# BGM11S12F256GA register map
File version: 4.0.0
CPU: CM4 r0p1, little endian, no MPU, no FPU, 0x3 interrupt priority bits, 0x0 interrupts
Registers are 32-bit, read-write, reset 0x0 unless marked. A register's access mark holds for its fields unless they carry their own. Offsets are from the block's base; [hi:lo] are bit positions; 'fields as' and 'values as' point back to an identical list.

## EMU
Base 0x400E3000
0x00 CTRL — Control Register
  [1] EM2BLOCK — Energy Mode 2 Block
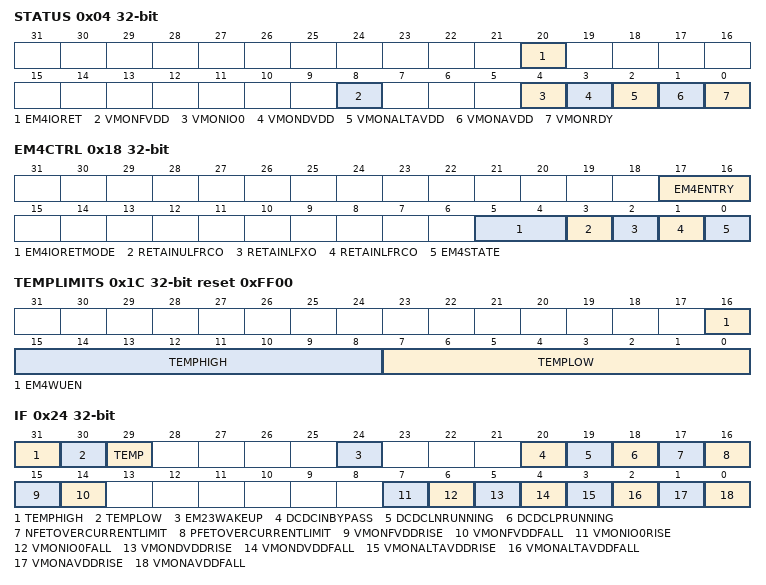
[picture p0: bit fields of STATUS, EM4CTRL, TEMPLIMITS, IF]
0x04 STATUS ro
  [20] EM4IORET — IO Retention Status
  [8] VMONFVDD — VMON VDDFLASH Channel
  [4] VMONIO0 — VMON IOVDD0 Channel
  [3] VMONDVDD — VMON DVDD Channel
  [2] VMONALTAVDD — Alternate VMON AVDD Channel
  [1] VMONAVDD — VMON AVDD Channel
  [0] VMONRDY — VMON Ready
0x08 LOCK — Configuration Lock Register
  [15:0] LOCKKEY — Configuration Lock Key
    0=UNLOCKED; 1=LOCKED
0x0C RAM0CTRL — Memory Control Register
  [3:0] RAMPOWERDOWN — RAM0 Blockset Power-down
    0=NONE (None of the RAM blocks powered down); 8=BLK4 (Power down RAM blocks 4 and above); 12=BLK3TO4 (Power down RAM blocks 3 and above); 14=BLK2TO4 (Power down RAM blocks 2 and above); 15=BLK1TO4 (Power down RAM blocks 1 and above)
0x10 CMD wo — Command Register
  [0] EM4UNLATCH
0x18 EM4CTRL — EM4 Control Register
  [17:16] EM4ENTRY wo — Energy Mode 4 Entry
  [5:4] EM4IORETMODE — EM4 IO Retention Disable
    0=DISABLE (No Retention: Pads enter reset state when entering EM4); 1=EM4EXIT (Retention through EM4: Pads enter reset state when exiting EM4); 2=SWUNLATCH (Retention through EM4 and Wakeup: software writes UNLATCH register to remove retention)
  [3] RETAINULFRCO — ULFRCO Retain During EM4S
  [2] RETAINLFXO — LFXO Retain During EM4
  [1] RETAINLFRCO — LFRCO Retain During EM4
  [0] EM4STATE — Energy Mode 4 State
0x1C TEMPLIMITS reset 0xFF00 — Temperature Limits for Interrupt Generation
  [16] EM4WUEN — Enable EM4 Wakeup Due to Low/high Temperature
  [15:8] TEMPHIGH — Temperature High Limit
  [7:0] TEMPLOW — Temperature Low Limit
0x20 TEMP ro — Value of Last Temperature Measurement
  [7:0] TEMP — Temperature Measurement
0x24 IF ro — Interrupt Flag Register
  [31] TEMPHIGH — Temperature High Limit Reached
  [30] TEMPLOW — Temperature Low Limit Reached
  [29] TEMP — New Temperature Measurement Valid
  [24] EM23WAKEUP — Wakeup IRQ From EM2 and EM3
  [20] DCDCINBYPASS — DCDC is in Bypass
  [19] DCDCLNRUNNING — LN Mode is Running
  [18] DCDCLPRUNNING — LP Mode is Running
  [17] NFETOVERCURRENTLIMIT — NFET Current Limit Hit
  [16] PFETOVERCURRENTLIMIT — PFET Current Limit Hit
  [15] VMONFVDDRISE — VMON VDDFLASH Channel Rise
  [14] VMONFVDDFALL — VMON VDDFLASH Channel Fall
  [7] VMONIO0RISE — VMON IOVDD0 Channel Rise
  [6] VMONIO0FALL — VMON IOVDD0 Channel Fall
  [5] VMONDVDDRISE — VMON DVDD Channel Rise
  [4] VMONDVDDFALL — VMON DVDD Channel Fall
  [3] VMONALTAVDDRISE — Alternate VMON AVDD Channel Rise
  [2] VMONALTAVDDFALL — Alternate VMON AVDD Channel Fall
  [1] VMONAVDDRISE — VMON AVDD Channel Rise
  [0] VMONAVDDFALL — VMON AVDD Channel Fall
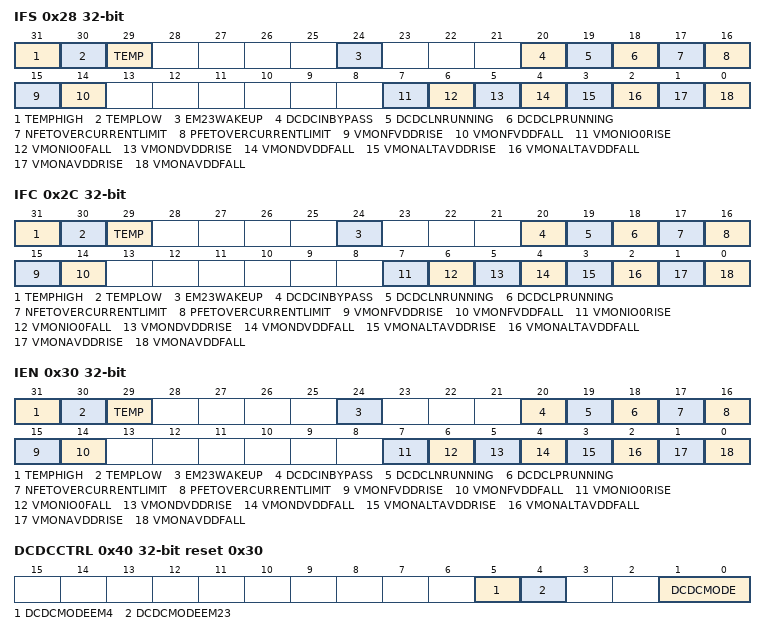
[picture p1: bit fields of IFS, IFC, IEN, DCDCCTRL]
0x28 IFS wo — Interrupt Flag Set Register
  [31] TEMPHIGH — Set TEMPHIGH Interrupt Flag
  [30] TEMPLOW — Set TEMPLOW Interrupt Flag
  [29] TEMP — Set TEMP Interrupt Flag
  [24] EM23WAKEUP — Set EM23WAKEUP Interrupt Flag
  [20] DCDCINBYPASS — Set DCDCINBYPASS Interrupt Flag
  [19] DCDCLNRUNNING — Set DCDCLNRUNNING Interrupt Flag
  [18] DCDCLPRUNNING — Set DCDCLPRUNNING Interrupt Flag
  [17] NFETOVERCURRENTLIMIT — Set NFETOVERCURRENTLIMIT Interrupt Flag
  [16] PFETOVERCURRENTLIMIT — Set PFETOVERCURRENTLIMIT Interrupt Flag
  [15] VMONFVDDRISE — Set VMONFVDDRISE Interrupt Flag
  [14] VMONFVDDFALL — Set VMONFVDDFALL Interrupt Flag
  [7] VMONIO0RISE — Set VMONIO0RISE Interrupt Flag
  [6] VMONIO0FALL — Set VMONIO0FALL Interrupt Flag
  [5] VMONDVDDRISE — Set VMONDVDDRISE Interrupt Flag
  [4] VMONDVDDFALL — Set VMONDVDDFALL Interrupt Flag
  [3] VMONALTAVDDRISE — Set VMONALTAVDDRISE Interrupt Flag
  [2] VMONALTAVDDFALL — Set VMONALTAVDDFALL Interrupt Flag
  [1] VMONAVDDRISE — Set VMONAVDDRISE Interrupt Flag
  [0] VMONAVDDFALL — Set VMONAVDDFALL Interrupt Flag
0x2C IFC wo — Interrupt Flag Clear Register
  [31] TEMPHIGH — Clear TEMPHIGH Interrupt Flag
  [30] TEMPLOW — Clear TEMPLOW Interrupt Flag
  [29] TEMP — Clear TEMP Interrupt Flag
  [24] EM23WAKEUP — Clear EM23WAKEUP Interrupt Flag
  [20] DCDCINBYPASS — Clear DCDCINBYPASS Interrupt Flag
  [19] DCDCLNRUNNING — Clear DCDCLNRUNNING Interrupt Flag
  [18] DCDCLPRUNNING — Clear DCDCLPRUNNING Interrupt Flag
  [17] NFETOVERCURRENTLIMIT — Clear NFETOVERCURRENTLIMIT Interrupt Flag
  [16] PFETOVERCURRENTLIMIT — Clear PFETOVERCURRENTLIMIT Interrupt Flag
  [15] VMONFVDDRISE — Clear VMONFVDDRISE Interrupt Flag
  [14] VMONFVDDFALL — Clear VMONFVDDFALL Interrupt Flag
  [7] VMONIO0RISE — Clear VMONIO0RISE Interrupt Flag
  [6] VMONIO0FALL — Clear VMONIO0FALL Interrupt Flag
  [5] VMONDVDDRISE — Clear VMONDVDDRISE Interrupt Flag
  [4] VMONDVDDFALL — Clear VMONDVDDFALL Interrupt Flag
  [3] VMONALTAVDDRISE — Clear VMONALTAVDDRISE Interrupt Flag
  [2] VMONALTAVDDFALL — Clear VMONALTAVDDFALL Interrupt Flag
  [1] VMONAVDDRISE — Clear VMONAVDDRISE Interrupt Flag
  [0] VMONAVDDFALL — Clear VMONAVDDFALL Interrupt Flag
0x30 IEN — Interrupt Enable Register
  [31] TEMPHIGH — TEMPHIGH Interrupt Enable
  [30] TEMPLOW — TEMPLOW Interrupt Enable
  [29] TEMP — TEMP Interrupt Enable
  [24] EM23WAKEUP — EM23WAKEUP Interrupt Enable
  [20] DCDCINBYPASS — DCDCINBYPASS Interrupt Enable
  [19] DCDCLNRUNNING — DCDCLNRUNNING Interrupt Enable
  [18] DCDCLPRUNNING — DCDCLPRUNNING Interrupt Enable
  [17] NFETOVERCURRENTLIMIT — NFETOVERCURRENTLIMIT Interrupt Enable
  [16] PFETOVERCURRENTLIMIT — PFETOVERCURRENTLIMIT Interrupt Enable
  [15] VMONFVDDRISE — VMONFVDDRISE Interrupt Enable
  [14] VMONFVDDFALL — VMONFVDDFALL Interrupt Enable
  [7] VMONIO0RISE — VMONIO0RISE Interrupt Enable
  [6] VMONIO0FALL — VMONIO0FALL Interrupt Enable
  [5] VMONDVDDRISE — VMONDVDDRISE Interrupt Enable
  [4] VMONDVDDFALL — VMONDVDDFALL Interrupt Enable
  [3] VMONALTAVDDRISE — VMONALTAVDDRISE Interrupt Enable
  [2] VMONALTAVDDFALL — VMONALTAVDDFALL Interrupt Enable
  [1] VMONAVDDRISE — VMONAVDDRISE Interrupt Enable
  [0] VMONAVDDFALL — VMONAVDDFALL Interrupt Enable
0x34 PWRLOCK — Regulator and Supply Lock Register
  [15:0] LOCKKEY — Regulator and Supply Configuration Lock Key
    0=UNLOCKED; 1=LOCKED
0x38 PWRCFG — Power Configuration Register
  [3:0] PWRCFG — Power Configuration
    0=STARTUP (Power up configuration. Works with any external configuration.); 2=DCDCTODVDD (Configured: DCDC control logic is enabled.)
0x3C PWRCTRL — Power Control Register
  [5] ANASW — Analog Switch Selection
0x40 DCDCCTRL reset 0x30 — DCDC Control
  [5] DCDCMODEEM4 — DCDC Mode EM4H
  [4] DCDCMODEEM23
  [1:0] DCDCMODE — Regulator Mode
    0=BYPASS (DCDC regulator is operating in bypass mode. Prior to configuring DCDCMODE=BYPASS, software must set EMU_DCDCCLIMCTRL.BYPLIMEN=1 to prevent excessive current between VREGVDD and DVDD supplies.); 1=LOWNOISE (DCDC regulator is operating in low noise mode.); 2=LOWPOWER (DCDC regulator is operating in low power mode.); 3=OFF (DCDC regulator is off and the bypass switch is off. Note: DVDD must be supplied externally)
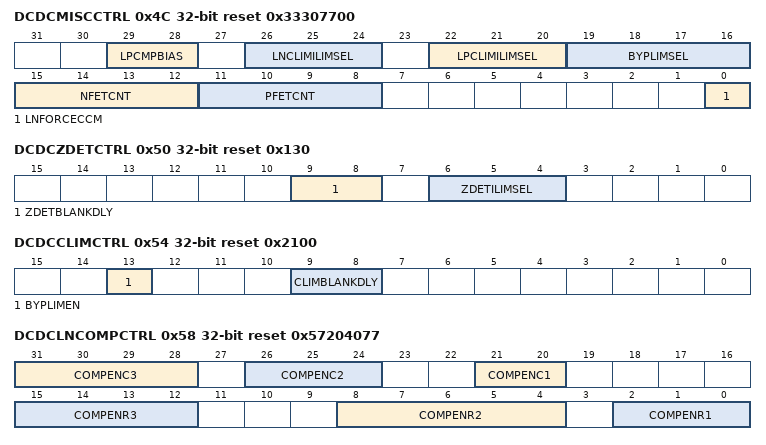
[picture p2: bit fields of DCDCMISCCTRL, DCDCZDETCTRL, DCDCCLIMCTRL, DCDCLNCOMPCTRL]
0x4C DCDCMISCCTRL reset 0x33307700 — DCDC Miscellaneous Control Register
  [29:28] LPCMPBIAS — LP Mode Comparator Bias Selection
    0=BIAS0 (Maximum load current less than 75uA.); 1=BIAS1 (Maximum load current less than 500uA.); 2=BIAS2 (Maximum load current less than 2.5mA.); 3=BIAS3 (Maximum load current less than 10mA.)
  [26:24] LNCLIMILIMSEL — Current Limit Level Selection for Current Limiter in LN Mode
  [22:20] LPCLIMILIMSEL — Current Limit Level Selection for Current Limiter in LP Mode
  [19:16] BYPLIMSEL — Current Limit in Bypass Mode
  [15:12] NFETCNT — NFET Switch Number Selection
  [11:8] PFETCNT — PFET Switch Number Selection
  [0] LNFORCECCM — Force DCDC Into CCM Mode in Low Noise Operation
0x50 DCDCZDETCTRL reset 0x130 — DCDC Power Train NFET Zero Current Detector Control Register
  [9:8] ZDETBLANKDLY — Reserved for internal use. Do not change.
  [6:4] ZDETILIMSEL — Reverse Current Limit Level Selection for Zero Detector
0x54 DCDCCLIMCTRL reset 0x2100 — DCDC Power Train PFET Current Limiter Control Register
  [13] BYPLIMEN — Bypass Current Limit Enable
  [9:8] CLIMBLANKDLY — Reserved for internal use. Do not change.
0x58 DCDCLNCOMPCTRL reset 0x57204077 — DCDC Low Noise Compensator Control Register
  [31:28] COMPENC3 — Low Noise Mode Compensator C3 Trim Value
  [26:24] COMPENC2 — Low Noise Mode Compensator C2 Trim Value
  [21:20] COMPENC1 — Low Noise Mode Compensator C1 Trim Value
  [15:12] COMPENR3 — Low Noise Mode Compensator R3 Trim Value
  [8:4] COMPENR2 — Low Noise Mode Compensator R2 Trim Value
  [2:0] COMPENR1 — Low Noise Mode Compensator R1 Trim Value
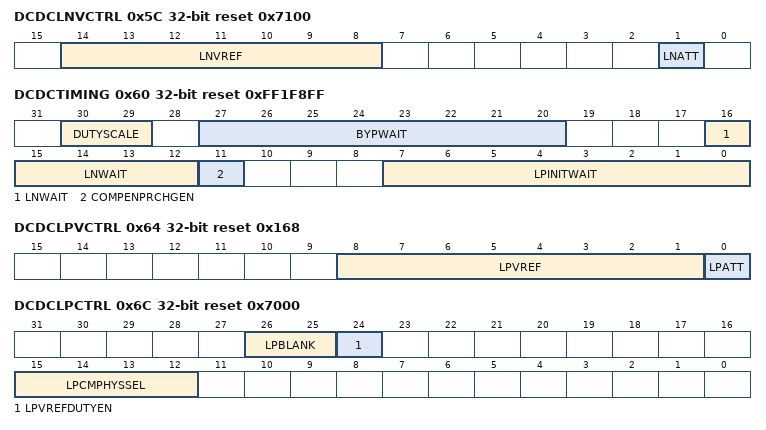
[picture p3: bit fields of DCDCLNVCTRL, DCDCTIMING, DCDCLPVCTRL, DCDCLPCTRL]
0x5C DCDCLNVCTRL reset 0x7100 — DCDC Low Noise Voltage Register
  [14:8] LNVREF — Low Noise Mode VREF Trim
  [1] LNATT — Low Noise Mode Feedback Attenuation
0x60 DCDCTIMING reset 0xFF1F8FF — DCDC Controller Timing Value Register
  [30:29] DUTYSCALE — Select Bias Duty Cycle Clock
  [27:20] BYPWAIT — Bypass Mode Transition From Low Power or Low Noise Modes Wait Wait
  [16:12] LNWAIT — Low Noise Controller Initialization Wait Time
  [11] COMPENPRCHGEN — LN Mode Precharge Enable
  [7:0] LPINITWAIT — Low Power Initialization Wait Time
0x64 DCDCLPVCTRL reset 0x168 — DCDC Low Power Voltage Register
  [8:1] LPVREF — LP Mode Reference Selection for EM23 and EM4H
  [0] LPATT — Low Power Feedback Attenuation
0x6C DCDCLPCTRL reset 0x7000 — DCDC Low Power Control Register
  [26:25] LPBLANK — Reserved for internal use. Do not change.
  [24] LPVREFDUTYEN — LP Mode Duty Cycling Enable
  [15:12] LPCMPHYSSEL — LP Mode Hysteresis Selection
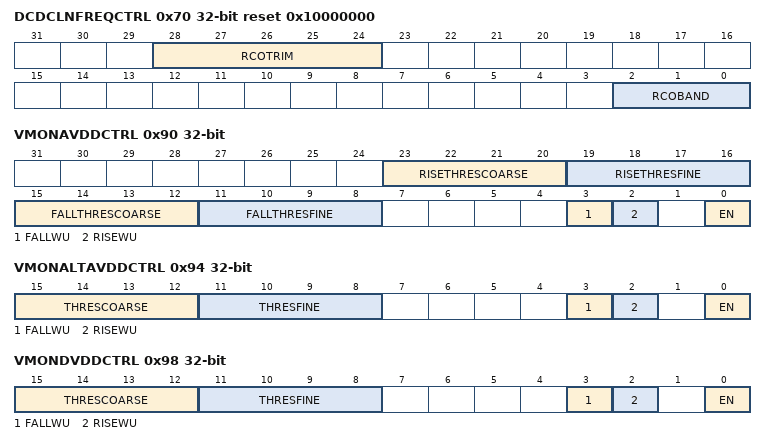
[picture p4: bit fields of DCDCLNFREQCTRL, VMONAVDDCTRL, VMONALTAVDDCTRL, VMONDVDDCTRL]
0x70 DCDCLNFREQCTRL reset 0x10000000 — DCDC Low Noise Controller Frequency Control
  [28:24] RCOTRIM — Reserved for internal use. Do not change.
  [2:0] RCOBAND — LN Mode RCO Frequency Band Selection
0x78 DCDCSYNC ro — DCDC Read Status Register
  [0] DCDCCTRLBUSY — DCDC CTRL Register Transfer Busy
0x90 VMONAVDDCTRL — VMON AVDD Channel Control
  [23:20] RISETHRESCOARSE — Rising Threshold Coarse Adjust
  [19:16] RISETHRESFINE — Rising Threshold Fine Adjust
  [15:12] FALLTHRESCOARSE — Falling Threshold Coarse Adjust
  [11:8] FALLTHRESFINE — Falling Threshold Fine Adjust
  [3] FALLWU — Fall Wakeup
  [2] RISEWU — Rise Wakeup
  [0] EN — Enable
0x94 VMONALTAVDDCTRL — Alternate VMON AVDD Channel Control
  [15:12] THRESCOARSE — Threshold Coarse Adjust
  [11:8] THRESFINE — Threshold Fine Adjust
  [3] FALLWU — Fall Wakeup
  [2] RISEWU — Rise Wakeup
  [0] EN — Enable
0x98 VMONDVDDCTRL — VMON DVDD Channel Control
  fields as VMONALTAVDDCTRL
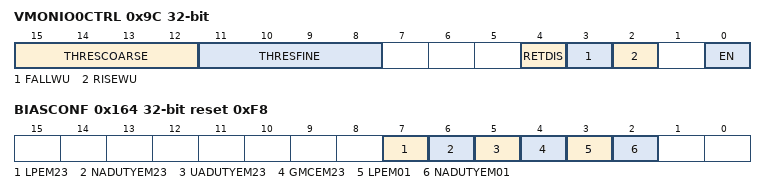
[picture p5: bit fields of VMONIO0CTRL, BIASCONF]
0x9C VMONIO0CTRL — VMON IOVDD0 Channel Control
  [15:12] THRESCOARSE — Threshold Coarse Adjust
  [11:8] THRESFINE — Threshold Fine Adjust
  [4] RETDIS — EM4 IO0 Retention Disable
  [3] FALLWU — Fall Wakeup
  [2] RISEWU — Rise Wakeup
  [0] EN — Enable
0x164 BIASCONF reset 0xF8 — Configurations Related to the Bias
  [7] LPEM23 — LP in EM234
  [6] NADUTYEM23 — NA DUTY in EM234
  [5] UADUTYEM23 — UADUTY in EM234
  [4] GMCEM23 — GMC in EM234
  [3] LPEM01 — LP in EM01
  [2] NADUTYEM01 — NA DUTY in EM01
0x190 TESTLOCK
  [15:0] LOCKKEY — Configuration Lock Key
    0=UNLOCKED; 1=LOCKED
0x19C BIASTESTCTRL — Test Control Register for Regulator and BIAS
  [3] BIAS_RIP_RESET — Reset Bias Ripple Counter
